# SPC1068 register map
File version: 20180100_70611510
CPU: CM3 r2p1, little endian, MPU, no FPU, 4 interrupt priority bits
Registers are 32-bit, read-write, reset 0x0 unless marked. A register's access mark holds for its fields unless they carry their own. Offsets are from the block's base; [hi:lo] are bit positions; {n}, {i} and the like mark numbered series; 'fields as' and 'values as' point back to an identical list.

## ADC — Analog Digital converter
Base 0x4000A000
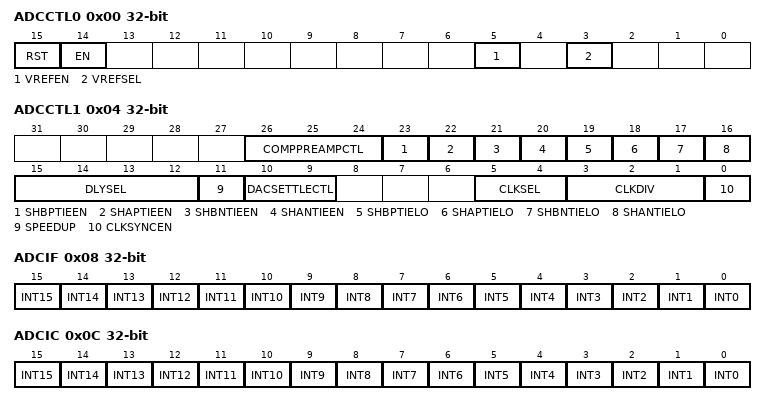
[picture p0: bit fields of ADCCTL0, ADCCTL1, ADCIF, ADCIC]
0x00 ADCCTL0 — ADC Control Register 0
  [15] RST — ADC registers Reset
    0=NO_EFFECT (Nothing change); 1=RESET_ADC (Reset ADC registers to Default value)
  [14] EN — ADC enable
    0=DISABLE_ADC; 1=ENABLE_ADC
  [5] VREFEN — ADC reference buffer enable
    0=DISABLE_REF_BUFF (Disable reference buffer); 1=ENABLE_REF_BUFF (Enable reference buffer)
  [3] VREFSEL — Select reference source for reference buffer
    0=INTERNAL_REF (Select internal reference source); 1=EXTERNAL_REF (Select external reference source)
0x04 ADCCTL1 — ADC Control Register 1
  [26:24] COMPPREAMPCTL — Comparator pre-amplifier time control
    0=1dot23_NS (1.23ns); 1=1dot75_NS (1.75ns); 2=2dot20_NS (2.20ns); 3=2dot69_NS (2.69ns); 4=2dot99_NS (2.99ns); 5=3dot47_NS (3.47ns); 6=3dot91_NS (3.91ns); 7=4dot40_NS (4.40ns)
  [23] SHBPTIEEN — Control bit for forcing positive input of SHB
    0=SHB_POSITIVE_DISABLE (Disable the function of forcing positive input of SHB); 1=SHB_POSITIVE_ENABLE (Enable the function of forcing positive input of SHB)
  [22] SHAPTIEEN — Control bit for forcing positive input of SHA
    0=SHA_POSITIVE_DISABLE (Disable the function of forcing positive input of SHA); 1=SHA_POSITIVE_ENABLE (Enable the function of forcing positive input of SHA)
  [21] SHBNTIEEN — Control bit for forcing negative input of SHB
    0=SHB_NEGATIVE_DISABLE (Disable the function of forcing negative input of SHB); 1=SHB_NEGATIVE_ENABLE (Enable the function of forcing negative input of SHB)
  [20] SHANTIEEN — Control bit for forcing negative input of SHA
    0=SHA_NEGATIVE_DISABLE (Disable the function of forcing negative input of SHA); 1=SHA_NEGATIVE_ENABLE (Enable the function of forcing negative input of SHA)
  [19] SHBPTIELO — Tie-high/low selection for forcing positive input of SHB
    0=SHB_POSITIVE_TIE_HIGH (Tie-high of the positive input of SHB); 1=SHB_POSITIVE_TIE_LOW (Tie-low of the positive input of SHB)
  [18] SHAPTIELO — Tie-high/low selection for forcing positive input of SHA
    0=SHA_POSITIVE_TIE_HIGH (Tie-high of the positive input of SHA); 1=SHA_POSITIVE_TIE_LOW (Tie-low of the positive input of SHA)
  [17] SHBNTIELO — Tie-high/low selection for forcing negative input of SHB
    0=SHB_NEGATIVE_TIE_HIGH (Tie-high of the negative input of SHB); 1=SHB_NEGATIVE_TIE_LOW (Tie-low of the negative input of SHB)
  [16] SHANTIELO — Tie-high/low selection for forcing negative input of SHA
    0=SHA_NEGATIVE_TIE_HIGH (Tie-high of the negative input of SHA); 1=SHA_NEGATIVE_TIE_LOW (Tie-low of the negative input of SHA)
  [15:12] DLYSEL — Delay adjustment of ADC front-end. DLYSEL[3]: Non-overlap selection 1ns/0.5ns(1/0) from convert to sample. DLYSEL[2]: Delay selection 1ns/0.5ns(1/0) from sample_cm to sample_in. DLYSEL[1]: CDAC Initial selection 1ns/0.5ns(1/0). DLYSEL[0]: Delay selection 1ns/0.5ns(1/0) from CDAC released to conversion starting
  [11] SPEEDUP — ADC Speed-up mode control
    0=DISABLE (Disable speed-up mode); 1=ENABLE (Enable speed-up mode)
  [10:9] DACSETTLECTL — DAC settling control for ADC conversion time.
    0=125ns; 1=150ns; 2=175ns; 3=200ns
  [5:4] CLKSEL — Select clock source in ADC front-end
    0=RCO (RCO clock); 1=XO (XO clock); 2=PLL (PLL clock); 3=ADCCLK (ADC clock)
  [3:1] CLKDIV — Select division for clk source in ADC front-end
    0=Fclk; 1=Fclk/2; 2=Fclk/4; 3=Fclk/8; 4=Fclk/16; 5=Fclk/32; 6=Fclk/64; 7=Fclk/128
  [0] CLKSYNCEN — Analog clk to resynchronize mcu control signal
    0=DISABLE (Disable this function); 1=ENABLE (Enable this function)
0x08 ADCIF ro — ADC Interrupt Flag Register
  [n] INT{n} (n=0..15) — Flag signal indicates if ADC Interrupt {n} is generated
    0=NOT_OCCUR (ADC Interrupt {n} isn't generated); 1=OCCUR (ADC Interrupt {n} is generated)
0x0C ADCIC wo — ADC Interrupt Flag Clear Register
  [n] INT{n} (n=0..15) — ADC Interrupt {n} flag clear bit
    0=NO_EFFECT (No clear); 1=CLEAR_FLAG (Clear ADC interrupt {n} flag)
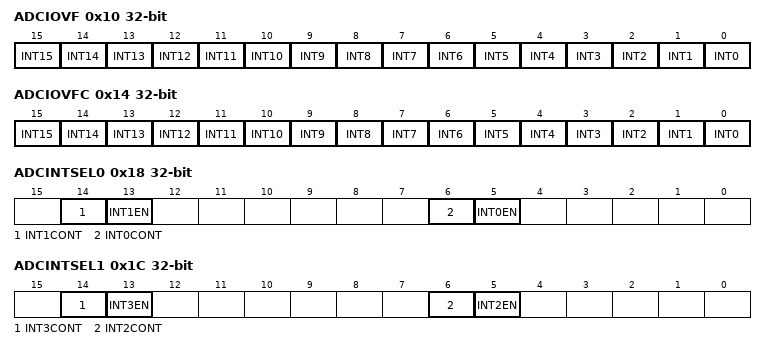
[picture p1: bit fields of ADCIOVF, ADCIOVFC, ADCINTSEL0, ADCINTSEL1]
0x10 ADCIOVF ro — ADC Interrupt Overflow Flag Register
  [n] INT{n} (n=0..15) — ADC Interrupt {n} overflow flag
    0=NOT_OCCUR (No overflow); 1=OCCUR (ADC Interrupt {n} overflow)
0x14 ADCIOVFC wo — ADC Interrupt Overflow Flag Clear Register
  [n] INT{n} (n=0..15) — ADC Interrupt {n} overflow flag clear bit
    0=NO_EFFECT (No clear); 1=CLEAR_FLAG (Clear ADC Interrupt {n} overflow flag)
0x18 ADCINTSEL0 — ADC Interrupt Select Register 0
  [14] INT1CONT — ADC Interrupt 1 continuous mode enable
    0=CONTINUE_MODE_DISABLE (No further ADC Interrupt 1 is generated unless the flag bit is clear by user); 1=CONTINUE_MODE_ENABLE (ADC Interrupt 1 is generated whenever an EOC pulse happen irrespective whether the flag bit is clear)
  [13] INT1EN — ADC Interrupt 1 enable
    0=DISABLE (Disable ADC Interrupt 1); 1=ENABLE (Enable ADC Interrupt 1)
  [6] INT0CONT — ADC interrupt 0 continuous mode enable
    0=CONTINUE_MODE_DISABLE (No further ADC Interrupt 0 is generated unless the flag bit is clear by user); 1=CONTINUE_MODE_ENABLE (ADC Interrupt 0 is generated whenever an EOC pulse happen irrespective whether the flag bit is clear)
  [5] INT0EN — ADC interrupt 0 enable
    0=DISABLE (Disable ADC Interrupt 0); 1=ENABLE (Enable ADC Interrupt 0)
0x1C ADCINTSEL1 — ADC Interrupt Select Register 1
  [14] INT3CONT — ADC interrupt 3 continuous mode enable
    0=CONTINUE_MODE_DISABLE (No further ADC Interrupt 3 is generated unless the flag bit is clear by user); 1=CONTINUE_MODE_ENABLE (ADC Interrupt 3 is generated whenever an EOC pulse happen irrespective whether the flag bit is clear)
  [13] INT3EN — ADC interrupt 3 enable
    0=DISABLE (Disable ADC Interrupt 3); 1=ENABLE (Enable ADC Interrupt 3)
  [6] INT2CONT — ADC interrupt 2 continuous mode enable
    0=CONTINUE_MODE_DISABLE (No further ADC Interrupt 2 is generated unless the flag bit is clear by user); 1=CONTINUE_MODE_ENABLE (ADC Interrupt 2 is generated whenever an EOC pulse happen irrespective whether the flag bit is clear)
  [5] INT2EN — ADC interrupt 2 enable
    0=DISABLE (Disable ADC Interrupt 2); 1=ENABLE (Enable ADC Interrupt 2)
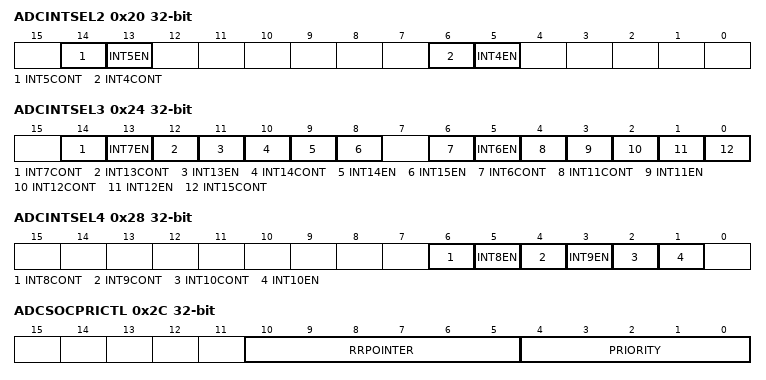
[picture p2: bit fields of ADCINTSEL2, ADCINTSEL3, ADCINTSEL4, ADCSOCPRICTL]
0x20 ADCINTSEL2 — ADC Interrupt Select Register 2
  [14] INT5CONT — ADC interrupt 5 continuous mode enable
    0=CONTINUE_MODE_DISABLE (No further ADC Interrupt 5 is generated unless the flag bit is clear by user); 1=CONTINUE_MODE_ENABLE (ADC Interrupt 5 is generated whenever an EOC pulse happen irrespective whether the flag bit is clear)
  [13] INT5EN — ADC interrupt 5 enable
    0=DISABLE (Disable ADC Interrupt 5); 1=ENABLE (Enable ADC Interrupt 5)
  [6] INT4CONT — ADC interrupt 4 continuous mode enable
    0=CONTINUE_MODE_DISABLE (No further ADC Interrupt 4 is generated unless the flag bit is clear by user); 1=CONTINUE_MODE_ENABLE (ADC Interrupt 4 is generated whenever an EOC pulse happen irrespective whether the flag bit is clear)
  [5] INT4EN — ADC interrupt 4 enable
    0=DISABLE (Disable ADC Interrupt 4); 1=ENABLE (Enable ADC Interrupt 4)
0x24 ADCINTSEL3 — ADC Interrupt Select Register 3
  [14] INT7CONT — ADC interrupt 7 continuous mode enable
    0=CONTINUE_MODE_DISABLE (No further ADC Interrupt 7 is generated unless the flag bit is clear by user); 1=CONTINUE_MODE_ENABLE (ADC Interrupt 7 is generated whenever an EOC pulse happen irrespective whether the flag bit is clear)
  [13] INT7EN — ADC interrupt 7 enable
    0=DISABLE (Disable ADC Interrupt 7); 1=ENABLE (Enable ADC Interrupt 7)
  [12] INT13CONT — ADC interrupt 13 continuous mode enable
    0=CONTINUE_MODE_DISABLE (No further ADC Interrupt 13 is generated unless the flag bit is clear by user); 1=CONTINUE_MODE_ENABLE (ADC Interrupt 13 is generated whenever an EOC pulse happen irrespective whether the flag bit is clear)
  [11] INT13EN — ADC interrupt 13 enable
    0=DISABLE (Disable ADC Interrupt 13); 1=ENABLE (Enable ADC Interrupt 13)
  [10] INT14CONT — ADC interrupt 14 continuous mode enable
    0=CONTINUE_MODE_DISABLE (No further ADC Interrupt 14 is generated unless the flag bit is clear by user); 1=CONTINUE_MODE_ENABLE (ADC Interrupt 14 is generated whenever an EOC pulse happen irrespective whether the flag bit is clear)
  [9] INT14EN — ADC interrupt 14 enable
    0=DISABLE (Disable ADC Interrupt 14); 1=ENABLE (Enable ADC Interrupt 14)
  [8] INT15EN — ADC interrupt 15 enable
    0=DISABLE (Disable ADC Interrupt 15); 1=ENABLE (Enable ADC Interrupt 15)
  [6] INT6CONT — ADC interrupt 6 continuous mode enable
    0=CONTINUE_MODE_DISABLE (No further ADC Interrupt 6 is generated unless the flag bit is clear by user); 1=CONTINUE_MODE_ENABLE (ADC Interrupt 6 is generated whenever an EOC pulse happen irrespective whether the flag bit is clear)
  [5] INT6EN — ADC interrupt 6 enable
    0=DISABLE (Disable ADC Interrupt 6); 1=ENABLE (Enable ADC Interrupt 6)
  [4] INT11CONT — ADC interrupt 11 continuous mode enable
    0=CONTINUE_MODE_DISABLE (No further ADC Interrupt 11 is generated unless the flag bit is clear by user); 1=CONTINUE_MODE_ENABLE (ADC Interrupt 11 is generated whenever an EOC pulse happen irrespective whether the flag bit is clear)
  [3] INT11EN — ADC interrupt 11 enable
    0=DISABLE (Disable ADC Interrupt 11); 1=ENABLE (Enable ADC Interrupt 11)
  [2] INT12CONT — ADC interrupt 12 continuous mode enable
    0=CONTINUE_MODE_DISABLE (No further ADC Interrupt 12 is generated unless the flag bit is clear by user); 1=CONTINUE_MODE_ENABLE (ADC Interrupt 12 is generated whenever an EOC pulse happen irrespective whether the flag bit is clear)
  [1] INT12EN — ADC interrupt 12 enable
    0=DISABLE (Disable ADC Interrupt 12); 1=ENABLE (Enable ADC Interrupt 12)
  [0] INT15CONT — ADC interrupt 15 continuous mode enable
    0=CONTINUE_MODE_DISABLE (No further ADC Interrupt 15 is generated unless the flag bit is clear by user); 1=CONTINUE_MODE_ENABLE (ADC Interrupt 15 is generated whenever an EOC pulse happen irrespective whether the flag bit is clear)
0x28 ADCINTSEL4 — ADC Interrupt Select Register 4
  [6] INT8CONT — ADC interrupt 8 continuous mode enable
    0=CONTINUE_MODE_DISABLE (No further ADC Interrupt 8 is generated unless the flag bit is clear by user); 1=CONTINUE_MODE_ENABLE (ADC Interrupt 8 is generated whenever an EOC pulse happen irrespective whether the flag bit is clear)
  [5] INT8EN — ADC interrupt 8 enable
    0=DISABLE (Disable ADC Interrupt 8); 1=ENABLE (Enable ADC Interrupt 8)
  [4] INT9CONT — ADC interrupt 9 continuous mode enable
    0=CONTINUE_MODE_DISABLE (No further ADC Interrupt 9 is generated unless the flag bit is clear by user); 1=CONTINUE_MODE_ENABLE (ADC Interrupt 9 is generated whenever an EOC pulse happen irrespective whether the flag bit is clear)
  [3] INT9EN — ADC interrupt 9 enable
    0=DISABLE (Disable ADC Interrupt 9); 1=ENABLE (Enable ADC Interrupt 9)
  [2] INT10CONT — ADC interrupt 10 continuous mode enable
    0=CONTINUE_MODE_DISABLE (No further ADC Interrupt 10 is generated unless the flag bit is clear by user); 1=CONTINUE_MODE_ENABLE (ADC Interrupt 10 is generated whenever an EOC pulse happen irrespective whether the flag bit is clear)
  [1] INT10EN — ADC interrupt 10 enable
    0=DISABLE (Disable ADC Interrupt 10); 1=ENABLE (Enable ADC Interrupt 10)
0x2C ADCSOCPRICTL — ADC State of Conversion Priority Control Register
  [10:5] RRPOINTER ro — Round Ring Pointer. Holds the latest SOCx in Round Ring, and determine the next order of conversion.
    {v}=SOC{v} (SOC{v} was the latest SOC. SOC{v+1} is next one in Round Robin.) (v=0..14); 15=SOC15 (SOC15 was the latest SOC. SOC0 is next one in Round Robin.)
  [4:0] PRIORITY — SOC (State-machine of Conversion) Priority. Determines the cutoff point for priority mode and round arbitration of SOCs
    0=CUTOFF_AT_SOC0 (All SOCs priority follow the rule of round mode); 1=CUTOFF_AT_SOC1 (SOC0 are high priority, SOC1-SOC15 is in round mode); {v}=CUTOFF_AT_SOC{v} (SOC0-SOC{v-1} are high priority, SOC{v}-SOC15 is in round mode) (v=2..14); 15=CUTOFF_AT_SOC15 (SOC0-SOC14 are high priority, SOC15 is in round mode)
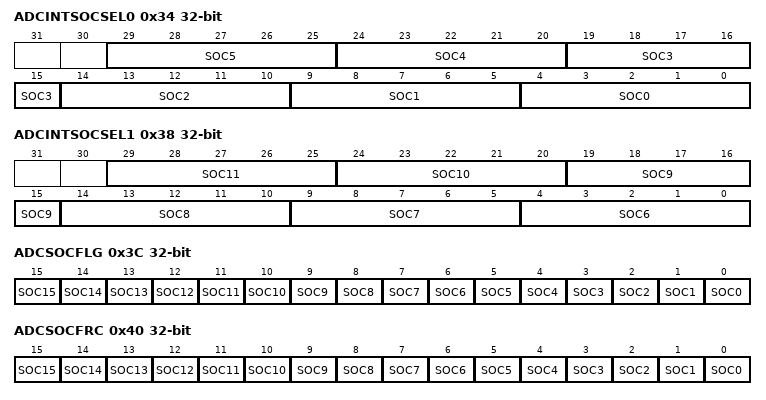
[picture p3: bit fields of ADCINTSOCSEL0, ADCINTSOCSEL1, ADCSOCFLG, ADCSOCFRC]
0x34 ADCINTSOCSEL0 — ADC Interrupt Trigger SOC Select Register 0
  [5n+4:5n] SOC{n} (n=0..5) — Select ADC interrupt source for SOC{n}. This Field will overrides the TRIGSEL Field in the ADCSOC{n}CTL Register. TRIGSEL Field will determine trigger source for SOC{n}.
    {v}=TRIG_BY_INT{v-16} (Select ADCINT{v-16} trigger SOC{n}) (v=16..31)
0x38 ADCINTSOCSEL1 — ADC Interrupt Trigger SOC Select Register 1
  [5n-26:5n-30] SOC{n} (n=6..11) — Select ADC interrupt source for SOC{n}. This Field will overrides the TRIGSEL Field in the ADCSOC{n}CTL Register. TRIGSEL Field will determine trigger source for SOC{n}.
    values as ADCINTSOCSEL0.SOC0
0x3C ADCSOCFLG ro — ADC SOC Flag Register
  [n] SOC{n} (n=0..15) — SOC{n} (State-machine of Conversion) Flag. This indicates state of each SOC. This bit will be automatically cleared when respective SOC0 conversion is started. If this bit receive both a request to set and a request to clear simultaneously, the bit will be set and ignore the request to clear. In this case, the overflow bit in the ADCSOCOVF Register will not be affected regardless of whether this bit was previously set or not.
    0=NO_PENDING (No sample pending for SOC{n}); 1=TRIG_RECEIVED (Trigger has been received and sample is pending for SOC{n})
0x40 ADCSOCFRC wo — ADC SOC Force Register
  [n] SOC{n} (n=11..15) — SOC{n} (State-machine of Conversion) Force Flag. This can be used to initialize a software initiated conversion. If ADCSOCFLG Register receive both a request to set from software and a request to clear from hardware simultaneously, then software has priority and ADCSOCFLG will be set. In this case, the overflow bit in the ADCSOCOVF Register will not be affected regardless of whether ADCSOCFLG bit was previously set or not.
    0=NO_EFFECT (No action); 1=FORCE_CONVERT (Force High to SOC{n} Flag bit in ADCSOCFLG Register)
  [10] SOC10 — SOC10 (State-machine of Conversion) Force Flag. This can be used to initialize a software initiated conversion. If ADCSOCFLG Register receive both a request to set from software and a request to clear from hardware simultaneously, then software has priority and ADCSOCFLG will be set. In this case, the overflow bit in the ADCSOCOVF Register will not be affected regardless of whether ADCSOCFLG bit was previously set or not.
    0=NO_EFFECT (No action.); 1=FORCE_CONVERT (Force High to SOC10 Flag bit in ADCSOCFLG Register.)
  [9] SOC9 — SOC9 (State-machine of Conversion) Force Flag. This can be used to initialize a software initiated conversion. If ADCSOCFLG Register receive both a request to set from software and a request to clear from hardware simultaneously, then software has priority and ADCSOCFLG will be set. In this case, the overflow bit in the ADCSOCOVF Register will not be affected regardless of whether ADCSOCFLG bit was previously set or not.
    0=NO_EFFECT (No action); 1=FORCE_CONVERT (Force High to SOC9 Flag bit in ADCSOCFLG Register)
  [8] SOC8 — SOC8 (State-machine of Conversion) Force Flag. This can be used to initialize a software initiated conversion. If ADCSOCFLG Register receive both a request to set from software and a request to clear from hardware simultaneously, then software has priority and ADCSOCFLG will be set. In this case, the overflow bit in the ADCSOCOVF Register will not be affected regardless of whether ADCSOCFLG bit was previously set or not.
    0=NO_EFFECT (No action); 1=FORCE_CONVERT (Force High to SOC8 Flag bit in ADCSOCFLG Register)
  [7] SOC7 — SOC7 (State-machine of Conversion) Force Flag. This can be used to initialize a software initiated conversion. If ADCSOCFLG Register receive both a request to set from software and a request to clear from hardware simultaneously, then software has priority and ADCSOCFLG will be set. In this case, the overflow bit in the ADCSOCOVF Register will not be affected regardless of whether ADCSOCFLG bit was previously set or not.
    0=NO_EFFECT (No action); 1=FORCE_CONVERT (Force High to SOC7 Flag bit in ADCSOCFLG Register.)
  [6] SOC6 — SOC6 (State-machine of Conversion) Force Flag. This can be used to initialize a software initiated conversion. If ADCSOCFLG Register receive both a request to set from software and a request to clear from hardware simultaneously, then software has priority and ADCSOCFLG will be set. In this case, the overflow bit in the ADCSOCOVF Register will not be affected regardless of whether ADCSOCFLG bit was previously set or not.
    0=NO_EFFECT (No action.); 1=FORCE_CONVERT (Force High to SOC6 Flag bit in ADCSOCFLG Register)
  [n] SOC{n} (n=0..5) — SOC{n} (State-machine of Conversion) Force Flag. This can be used to initialize a software initiated conversion. If ADCSOCFLG Register receive both a request to set from software and a request to clear from hardware simultaneously, then software has priority and ADCSOCFLG will be set. In this case, the overflow bit in the ADCSOCOVF Register will not be affected regardless of whether ADCSOCFLG bit was previously set or not.
    values as SOC11
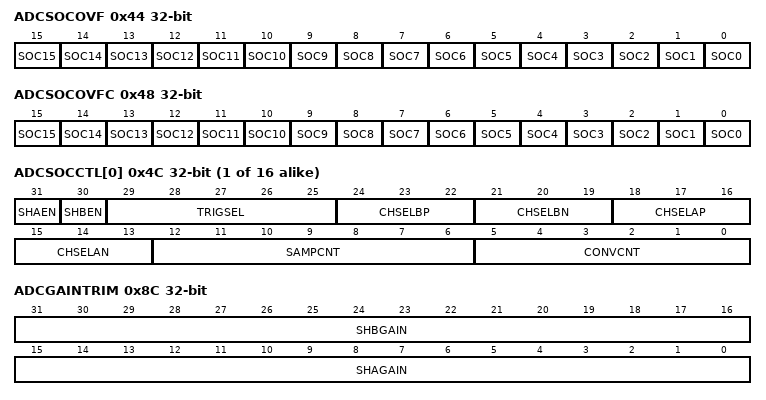
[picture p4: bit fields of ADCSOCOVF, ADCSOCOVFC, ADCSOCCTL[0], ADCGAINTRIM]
0x44 ADCSOCOVF ro — ADC SOC Overflow Register
  [n] SOC{n} (n=0..15) — SOC{n} (State-machine of Conversion) Overflow Flag. This indicates an SOC{n} event was generated while an existing SOC{n} event was already pending. This overflow flag can't stop SOC{n} events from being processing. It just show that a trigger was missed.
    0=NOT_OCCUR (No SOC{n} event overflow); 1=OCCUR (SOC{n} event overflow)
0x48 ADCSOCOVFC wo — ADC SOC Overflow Clear Register
  [n] SOC{n} (n=0..15) — Clear SOC{n} Overflow Flag. If this bit receive a request to set from software and hardware try to set respective SOC{n} overflow bit in ADCSOCOVF Register simultaneously, then hardware has priority and ADCSOCOVF Register will be set.
    0=NO_EFFECT (No clear); 1=CLEAR_FLAG (Clear SOC{n} Overflow Flag)
{0x4C+4i} ADCSOCCTL[{i}] (i=0..15) — ADC SOC0 Control Register
  [31] SHAEN — Enable Sample and Hold A(SHA) to sample input of CHSELAP and CHSELAN
    0=DISABLE (Disable SHA to sample); 1=ENABLE (Enable SHA to sample)
  [30] SHBEN — Enable Sample and Hold B(SHB) to sample input of CHSELBP and CHSELBN
    0=DISABLE (Disable SHB to sample); 1=ENABLE (Enable SHB to sample)
  [29:25] TRIGSEL — Select SOC0 Trigger Source. Configures which trigger source will set SOC0 flag in the ADCSOCFLG Register. The Flag will initiate a conversion to start once and the priority is given to SOC0. This setting can be overridden by the respective SOC0 Field in the ADCINTSOCSEL0~2 Registers.
    0=SOFTWARE (ADCTRIG0 - Software only); 1=TIMER0 (ADCTRIG1 - CPU Timer 0); 2=TIMER1 (ADCTRIG2 - CPU Timer 1); 3=TIMER2 (ADCTRIG3 - CPU Timer 2); 4=XINT2 (ADCTRIG4 - XINT2); 5=PWM0A (ADCTRIG5 - PWM0A); 6=PWM0B (ADCTRIG6 - PWM0B); 7=PWM1A (ADCTRIG7 - PWM1A); 8=PWM1B (ADCTRIG8 - PWM1B); 9=PWM2A (ADCTRIG9 - PWM2A); 10=PWM2B (ADCTRIG10 - PWM2B); 11=PWM3A (ADCTRIG11 - PWM3A); 12=PWM3B (ADCTRIG12 - PWM3B); 13=PWM4A (ADCTRIG13 - PWM4A); 14=PWM4B (ADCTRIG14 - PWM4B); 15=PWM5A (ADCTRIG15 - PWM5A); 16=PWM5B (ADCTRIG16 - PWM5B); 17=PWM6A (ADCTRIG17 - PWM6A); 18=PWM6B (ADCTRIG18 - PWM6B)
  [24:22] CHSELBP — Select channel to positive terminal of SHB for SOC0
    0=PGA2P_OUT (Positive output of PGA2); 1=PGA1P_OUT (Positive output of PGA1); 2=GND (VSSA); 3=TSENSOR1 (T-sensor output 1); {v}=ADC{v+4} (GPIO{v+5}) (v=4..7)
  [21:19] CHSELBN — Select channel to negative terminal of SHB for SOC0
    0=PGA2N_OUT (Negative output of PGA2); 1=PGA1N_OUT (Negative output of PGA1); 2=GND (VSSA); 3=TSENSOR0 (T-sensor output 0); {v}=ADC{v+8} (GPIO{v+9}) (v=4..7)
  [18:16] CHSELAP — Select channel to positive terminal of SHA for SOC0
    0=PGA0P_OUT (Positive output of PGA0); 1=PGA1P_OUT (Positive output of PGA1); 2=GND (VSSA); 3=VDD12; {v}=ADC{v-4} (GPIO{v-3}) (v=4..7)
  [15:13] CHSELAN — Select channel to negative terminal of SHA for SOC0
    0=PGA0N_OUT (Negative output of PGA0); 1=PGA1N_OUT (Negative output of PGA1); 2=GND (VSSA); 3=VDDA; {v}=ADC{v} (GPIO{v+1}) (v=4..7)
  [12:6] SAMPCNT — Select SOC0 Sample Window Size
  [5:0] CONVCNT — Select SOC0 Convert Window Size
0x8C ADCGAINTRIM
  [31:16] SHBGAIN — Gain Error Register 1. It will store the gain-error of SHB and ADC core.
  [15:0] SHAGAIN — Gain Error Register 0. It will store the gain-error of SHA and ADC core.
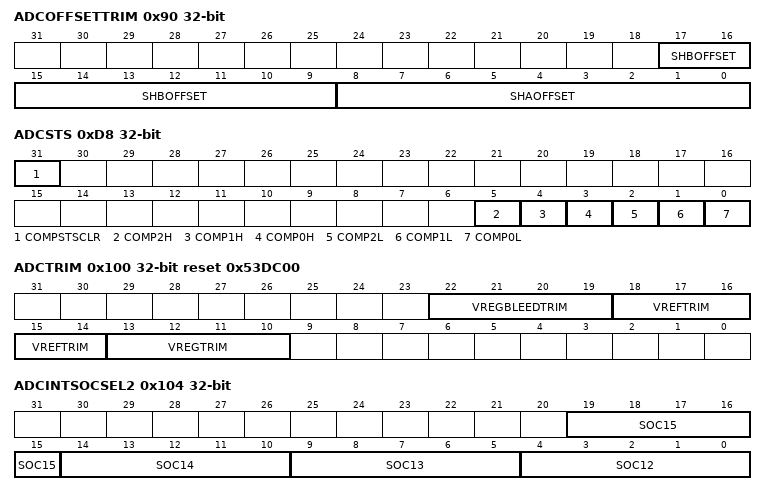
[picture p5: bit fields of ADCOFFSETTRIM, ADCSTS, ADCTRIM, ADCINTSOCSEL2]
0x90 ADCOFFSETTRIM
  [17:9] SHBOFFSET — Offset Error Register 1. It will store the offset-error of SHB and ADC core.
  [8:0] SHAOFFSET — Offset Error Register 0. It will store the offset-error of SHA and ADC core.
{0x98+4i} ADCRESULT[{i}] (i=0..15) ro — ADC Result Register 0
  [12:0] VAL — 13-bit ADC result - Sequential Sampling Mode. After the ADC completes a conversion of an SOC0, the digital result is placed in the corresponding ADCRESULT0 Register. - Simultaneous Sampling Mode. After the ADC completes a conversion of a channel pair, the digital results are found in the corresponding ADCRESULTx and ADCRESULTx+1 registers (assuming x is even). For example, for SOC0, the completed results of those conversions will be placed in ADCRESULT0 and ADCRESULT1.
0xD8 ADCSTS — ADC Status Register
  [31] COMPSTSCLR wo — Write 1 to clear latched comparator status(self-clear)
    0=NO_EFFECT (Has no effect); 1=CLEAR (Clear latched comparator status)
  [5] COMP2H ro — The output of comparator for high-voltage protection in PGA 2
    0=LOW (The output of comparator for high-voltage protection in PGA 2 is low); 1=HIGH (The output of comparator for high-voltage protection in PGA 2 is high)
  [4] COMP1H ro — The output of comparator for high-voltage protection in PGA 1
    0=LOW (The output of comparator for high-voltage protection in PGA 1 is low); 1=HIGH (The output of comparator for high-voltage protection in PGA 1 is high)
  [3] COMP0H ro — The output of comparator for high-voltage protection in PGA 0
    0=LOW (The output of comparator for high-voltage protection in PGA 0 is low); 1=HIGH (The output of comparator for high-voltage protection in PGA 0 is high)
  [2] COMP2L ro — The output of comparator for low-voltage protection in PGA 2
    0=LOW (The output of comparator for low-voltage protection in PGA 2 is low); 1=HIGH (The output of comparator for low-voltage protection in PGA 2 is high)
  [1] COMP1L ro — The output of comparator for low-voltage protection in PGA 1
    0=LOW (The output of comparator for low-voltage protection in PGA 1 is low); 1=HIGH (The output of comparator for low-voltage protection in PGA 1 is high)
  [0] COMP0L ro — The output of comparator for low-voltage protection in PGA 0
    0=LOW (The output of comparator for low-voltage protection in PGA 0 is low); 1=HIGH (The output of comparator for low-voltage protection in PGA 0 is high)
0xDC TSENSCTL — Temperature Sensor Control Register
  [6] EN — T-sensor enable
    0=DISABLE (Disable T-sensor); 1=ENABLE (Enable T-sensor)
0x100 ADCTRIM reset 0x53DC00 — ADC Trimming Control Register
  [22:19] VREGBLEEDTRIM — Trimming option (fine) for ADC 1.2V Regulator output
  [18:14] VREFTRIM — Trimming option of ADC 1.2V Reference
  [13:10] VREGTRIM — Trimming option (coarse) for ADC 1.2V Regulator output
0x104 ADCINTSOCSEL2 — ADC Interrupt Trigger SOC Select Register 2
  [5n-56:5n-60] SOC{n} (n=12..15) — Select ADC interrupt source for SOC{n}. This Field will overrides the TRIGSEL Field in the ADCSOC{n}CTL Register. TRIGSEL Field will determine trigger source for SOC{n}.
    values as ADCINTSOCSEL0.SOC0
